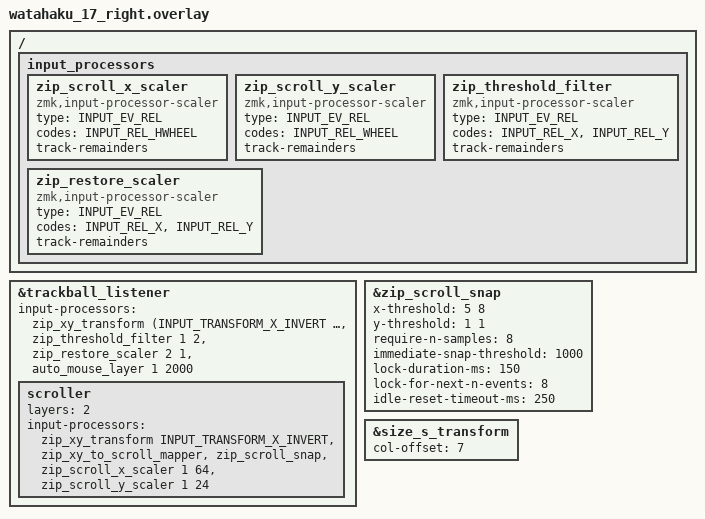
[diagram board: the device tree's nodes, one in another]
#include "watahaku_17.dtsi"
#include <input/processors.dtsi>
#include <dt-bindings/zmk/input_transform.h>
#include <dt-bindings/zmk/keys.h>
#include <zephyr/dt-bindings/input/input-event-codes.h>
#include <scroll-snap.dtsi>

/ {
    input_processors {
        zip_scroll_x_scaler: zip_scroll_x_scaler {
            compatible = "zmk,input-processor-scaler";
            #input-processor-cells = <2>;
            type = <INPUT_EV_REL>;
            codes = <INPUT_REL_HWHEEL>;
            track-remainders;
        };

        zip_scroll_y_scaler: zip_scroll_y_scaler {
            compatible = "zmk,input-processor-scaler";
            #input-processor-cells = <2>;
            type = <INPUT_EV_REL>;
            codes = <INPUT_REL_WHEEL>;
            track-remainders;
        };

        // Threshold filter: movements < threshold are rounded to 0
        zip_threshold_filter: zip_threshold_filter {
            compatible = "zmk,input-processor-scaler";
            #input-processor-cells = <2>;
            type = <INPUT_EV_REL>;
            codes = <INPUT_REL_X>, <INPUT_REL_Y>;
            track-remainders;
        };

        // Restore scaler after threshold filtering
        zip_restore_scaler: zip_restore_scaler {
            compatible = "zmk,input-processor-scaler";
            #input-processor-cells = <2>;
            type = <INPUT_EV_REL>;
            codes = <INPUT_REL_X>, <INPUT_REL_Y>;
            track-remainders;
        };
    };
};

&trackball_listener {
    // Normal mode: Standard speed (1.0x) with threshold filtering
    input-processors = <
        &zip_xy_transform (INPUT_TRANSFORM_X_INVERT | INPUT_TRANSFORM_Y_INVERT)
        &zip_threshold_filter 1 2    // Reduce to 50%: movements < 2 become 0
        &zip_restore_scaler 2 1      // Restore to 1.0x (0.5 × 2 = 1.0)
        &auto_mouse_layer 1 2000     // Activate layer 1 only if movement > threshold
    >;

    // Layer 2: Scroll mode
    scroller {
        layers = <2>;
        input-processors = <
            &zip_xy_transform INPUT_TRANSFORM_X_INVERT
            &zip_xy_to_scroll_mapper
            &zip_scroll_snap           // Snap scroll to nearest axis
            &zip_scroll_x_scaler 1 64  // X-axis: 1/64x scroll speed (original setting)
            &zip_scroll_y_scaler 1 24  // Y-axis: 1/24x scroll speed (original setting)
        >;
    };
};

// Customize scroll snap behavior
&zip_scroll_snap {
    x-threshold = <5 8>;           // Snap to X if |y/x| < 5/8 (0.625)
    y-threshold = <1 1>;           // Snap to Y if |y/x| > 1
    require-n-samples = <8>;       // Collect 8 samples before snapping (faster response)
    immediate-snap-threshold = <1000>;  // Snap immediately if movement exceeds 1000
    lock-duration-ms = <150>;      // Lock direction for 150ms
    lock-for-next-n-events = <8>;  // Keep direction for next 8 events
    idle-reset-timeout-ms = <250>; // Reset after 250ms idle
};

&size_s_transform {
    col-offset = <7>;
};

// &size_m_transform {
//     col-offset = <7>;
// };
